AUTOSAR XML (schema 4-3-0)
package /CollisionDetectionApplicationLayer/ApplicationPackage
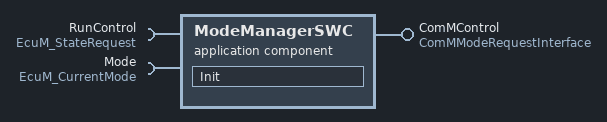
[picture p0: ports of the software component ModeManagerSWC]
  application sw component type ModeManagerSWC
    provide port ComMControl: provided-interface=ComMModeRequestInterface
    require port RunControl: required-interface=EcuM_StateRequest
    require port Mode: required-interface=EcuM_CurrentMode
    behavior ModeManagerSWCBehaviour: data-type-mapping=[EcuMFixedTypeMappings, ComMTypeMappings, TypeMappings], handle-termination-and-restart=NO-SUPPORT
      swc mode switch event InitEvent: start-on-event=Init, activation=ON-EXIT, mode=Mode.currentMode.STARTUP
      runnable Init: symbol=EcuModeManagerInit
        data-write-access:
          access dataWriteAccess_Init_ComMControl_requestedMode: accessed-variable=ComMControl.requestedMode
        sync call RunControl_RequestRUN: operation=RunControl.RequestRUN, timeout=0.0
  swc implementation ModeManagerSWCImpl: programming-language=C, vendor-id=0, behavior=ModeManagerSWCBehaviour
    code-descriptors:
      code src: artifact-descriptors=autosar-engineering-object={short-label=artifactDescriptor, category=artifactDescriptorCategory}
    resource consumption resourceConsumption
